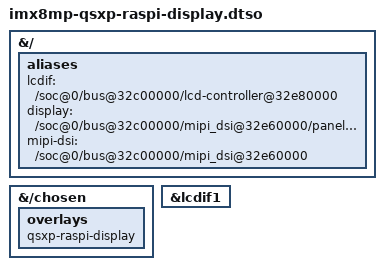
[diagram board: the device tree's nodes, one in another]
// SPDX-License-Identifier: (GPL-2.0 OR MIT)
/*
 * Copyright 2022 Lothar Waßmann <LW@KARO-electronics.de>
 *
 */

/dts-v1/;

/plugin/;

#include "includes/imx8m-karo-raspi-display.dtsi"

&{/} {
	aliases {
		lcdif = "/soc@0/bus@32c00000/lcd-controller@32e80000";
		display = "/soc@0/bus@32c00000/mipi_dsi@32e60000/panel@0";
		mipi-dsi = "/soc@0/bus@32c00000/mipi_dsi@32e60000";
	};
};

&{/chosen} {
	overlays {
		qsxp-raspi-display;
	};
};

&lcdif1 {
	status = "okay";
};
